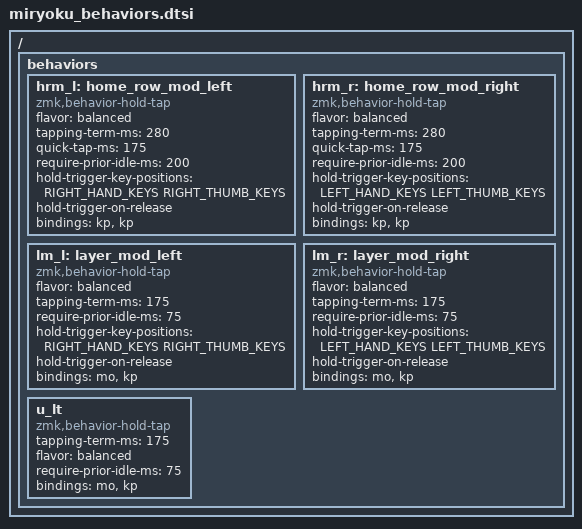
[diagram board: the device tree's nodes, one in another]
// Copyright 2022 Manna Harbour
// https://github.com/manna-harbour/miryoku

/ {
    #define LEFT_HAND_KEYS  0 1 2 3 4 10 11 12 13 14 20 21 22 23 24
    #define RIGHT_HAND_KEYS 5 6 7 8 9 15 16 17 18 19 25 26 27 28 29

    #define LEFT_THUMB_KEYS  32 33 34
    #define RIGHT_THUMB_KEYS 35 36 37 
};

/ {
  behaviors {
    // Left Home Row Mod (HRM)
    hrm_l: home_row_mod_left {
      compatible = "zmk,behavior-hold-tap";
      #binding-cells = <2>;
      flavor = "balanced"; // Recommended flavor for HRMs
      tapping-term-ms = <280>;
      quick-tap-ms = <175>;
      require-prior-idle-ms = <200>;
      // Hold is triggered immediately if the next key pressed is in the list
      // We want the hold (modifier) to trigger if we press a key on the RIGHT side
      hold-trigger-key-positions = <RIGHT_HAND_KEYS RIGHT_THUMB_KEYS>;
      
      // This is crucial for successfully combining two mods on the same hand
      hold-trigger-on-release;
      bindings = <&kp>, <&kp>; 
    };
    hrm_r: home_row_mod_right {
      compatible = "zmk,behavior-hold-tap";
      #binding-cells = <2>;
      flavor = "balanced"; 
      tapping-term-ms = <280>;
      quick-tap-ms = <175>;
      require-prior-idle-ms = <200>;
      // We want the hold (modifier) to trigger if we press a key on the LEFT side
      hold-trigger-key-positions = <LEFT_HAND_KEYS LEFT_THUMB_KEYS>;

      // This is crucial for successfully combining two mods on the same hand
      hold-trigger-on-release;
      bindings = <&kp>, <&kp>;
    };
    lm_l: layer_mod_left {
      compatible = "zmk,behavior-hold-tap";
      #binding-cells = <2>;
      flavor = "balanced";
      tapping-term-ms = <175>;
      require-prior-idle-ms = <75>;
      hold-trigger-key-positions = <RIGHT_HAND_KEYS RIGHT_THUMB_KEYS>;
      hold-trigger-on-release;
      bindings = <&mo>, <&kp>; 
    };
    lm_r: layer_mod_right {
      compatible = "zmk,behavior-hold-tap";
      #binding-cells = <2>;
      flavor = "balanced";
      tapping-term-ms = <175>;
      require-prior-idle-ms = <75>;
      hold-trigger-key-positions = <LEFT_HAND_KEYS LEFT_THUMB_KEYS>;
      hold-trigger-on-release;
      bindings = <&mo>, <&kp>;
    };
    u_lt: u_lt {
      compatible = "zmk,behavior-hold-tap";
      #binding-cells = <2>;
      tapping-term-ms = <175>;
      flavor = "balanced";
      require-prior-idle-ms = <75>;
      bindings = <&mo>, <&kp>;
    };
  };
};
